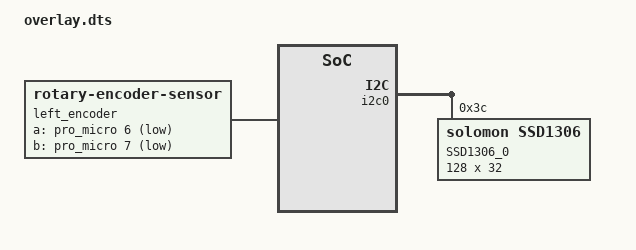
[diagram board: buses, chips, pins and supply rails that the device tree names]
/dts-v1/;

/ {
    chosen {
        zephyr,display = &display0;
    };

    left_encoder: encoder_left {
        compatible = "zmk,rotary-encoder-sensor";
        a-gpios = <&pro_micro 6 (GPIO_PULL_UP | GPIO_ACTIVE_LOW)>;
        b-gpios = <&pro_micro 7 (GPIO_PULL_UP | GPIO_ACTIVE_LOW)>;
        steps = <20>;
        status = "okay";
    };

    sensors {
        compatible = "zmk,keymap-sensors";
        sensors = <&left_encoder>;
    };
};

&i2c0 {
    display0: ssd1306@3c {
        compatible = "solomon,ssd1306";
        reg = <0x3c>;
        label = "SSD1306_0";
        width = <128>;
        height = <32>;
        status = "okay";
    };
};
